# CY8C3866AXI_040 register map
File version: 0.1
CY8C38
Registers are 8-bit, read-write, no defined reset value unless marked. A register's access mark holds for its fields unless they carry their own. Offsets are from the block's base; lines under a group give offsets from that group; [hi:lo] are bit positions; {n}, {i} and the like mark numbered series; 'fields as' and 'values as' point back to an identical list; <NAME> marks a mode.

## Memory map
0x00004382 RTC_1 size 0xF — RTC
0x00004394 USBUART size 0x1D0A — USBFS
0x000043A3 Blink_Timer size 0xB64
0x000043AA ADC size 0x17E0

## RTC_1 — RTC
Base 0x00004382
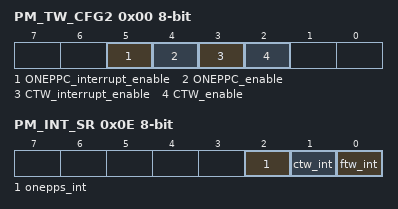
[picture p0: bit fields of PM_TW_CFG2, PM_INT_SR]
0x00 PM_TW_CFG2 — Power timers enable and interrupt enable configuration register
  [5] ONEPPC_interrupt_enable — When set and one pulse-per-second is enabled, an interrupt is issued when the pulse occurs
    1=Enabled (The ONEPPC interrupt is issued. Only if ONEPPC is enabled.); 0=Disabled (No ONEPPC interrupt is issued.)
  [4] ONEPPC_enable
    1=Enabled (The ONEPPC is enabled.); 0=Disabled (The ONEPPC is disabled.)
  [3] CTW_interrupt_enable — An interrupt issue when the CTW reaches the selected interval
    1=Enabled (The CTW interrupt is issued. Only if CTW is enabled.); 0=Disabled (No CTW interrupt is issued.)
  [2] CTW_enable
    1=Enabled (The CTW is enabled.); 0=Disabled (The CTW is disabled.)
0x0E PM_INT_SR — Power Manager Interrupt Status Register
  [2] onepps_int — When set, a onepps event has occured.
  [1] ctw_int — When set, a limited active ready event has occured
  [0] ftw_int — When set, a fast timewheel event has occured

## USBUART — USBFS
Base 0x00004394
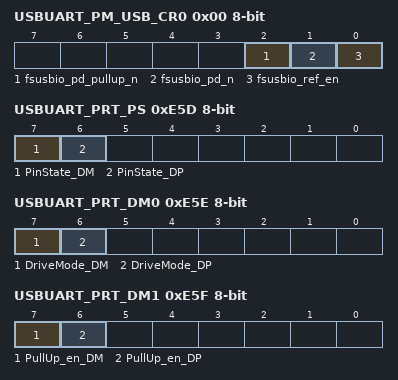
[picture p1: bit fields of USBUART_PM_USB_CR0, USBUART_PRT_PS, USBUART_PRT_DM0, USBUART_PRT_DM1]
0x00 USBUART_PM_USB_CR0 — USB Power Mode Control Register 0
  [2] fsusbio_pd_pullup_n, [1] fsusbio_pd_n, [0] fsusbio_ref_en
0x11 USBUART_PM_ACT_CFG — Active Power Mode Configuration Register
0x21 USBUART_PM_STBY_CFG — Standby Power Mode Configuration Register
0xE5D USBUART_PRT_PS — Port Pin State Register
  [7] PinState_DM ro, [6] PinState_DP ro
0xE5E USBUART_PRT_DM0 — Port Drive Mode Register
  [7] DriveMode_DM, [6] DriveMode_DP
0xE5F USBUART_PRT_DM1 — Port Drive Mode Register
  [7] PullUp_en_DM, [6] PullUp_en_DP
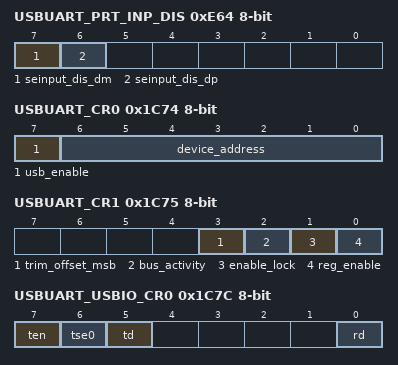
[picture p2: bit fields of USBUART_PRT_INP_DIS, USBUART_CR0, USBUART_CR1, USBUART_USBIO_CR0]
0xE64 USBUART_PRT_INP_DIS — Input buffer disable override
  [7] seinput_dis_dm, [6] seinput_dis_dp
0x1C6C USBUART_EP0_DR0 — bmRequestType
0x1C6D USBUART_EP0_DR1 — bRequest
0x1C6E USBUART_EP0_DR2 — wValueLo
0x1C6F USBUART_EP0_DR3 — wValueHi
0x1C70 USBUART_EP0_DR4 — wIndexLo
0x1C71 USBUART_EP0_DR5 — wIndexHi
0x1C72 USBUART_EP0_DR6 — lengthLo
0x1C73 USBUART_EP0_DR7 — lengthHi
0x1C74 USBUART_CR0 — USB Control Register 0
  [7] usb_enable, [6:0] device_address ro
0x1C75 USBUART_CR1 — USB Control Register 1
  [3] trim_offset_msb, [2] bus_activity, [1] enable_lock, [0] reg_enable
{0x1C6A+0x10*i} USBUART_SIE_EP{i}_CR0 (i=1..8) — The Endpoint{i} Control Register
0x1C7C USBUART_USBIO_CR0 — USBIO Control Register 0
  [7] ten, [6] tse0, [5] td, [0] rd ro
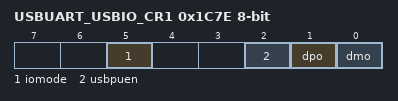
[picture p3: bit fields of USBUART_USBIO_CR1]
0x1C7E USBUART_USBIO_CR1 — USBIO Control Register 1
  [5] iomode, [2] usbpuen, [1] dpo ro, [0] dmo ro
0x1CF8 USBUART_BUF_SIZE — Dedicated Endpoint Buffer Size Register
0x1CFA USBUART_EP_ACTIVE — Endpoint Active Indication Register
0x1CFB USBUART_EP_TYPE — Endpoint Type (IN/OUT) Indication
0x1D09 USBUART_USB_CLK_EN — USB Block Clock Enable Register

## Blink_Timer
Base 0x000043A3
0x00 Blink_Timer_GLOBAL_ENABLE — PM.ACT.CFG
  [3:0] en_timer — Enable timer/counters.
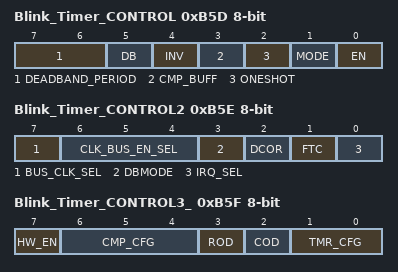
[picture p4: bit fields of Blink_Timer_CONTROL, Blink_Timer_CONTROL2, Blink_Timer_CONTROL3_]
0xB5D Blink_Timer_CONTROL — TMRx.CFG0
  [7:6] DEADBAND_PERIOD
  [5] DB — Deadband mode--Deadband phases phi1 and phi2 are outputted on CMP and TC output pins respectively.
    0=Timer (CMP and TC are output.); 1=Deadband (PHI1 (instead of CMP) and PHI2 (instead of TC) are output.)
  [4] INV — Invert sense of TIMEREN signal
  [3] CMP_BUFF — Buffer compare register. Compare register updates only on timer terminal count.
  [2] ONESHOT — Timer stops upon reaching stop condition defined by TMR_CFG bits. Can be restarted by asserting TIMER RESET or disabling and re-enabling block.
  [1] MODE — Mode. (0 = Timer; 1 = Comparator)
    0=Timer mode. CNT/CMP register holds timer count value.; 1=Comparator mode. CNT/CMP register holds comparator threshold value.
  [0] EN — Enables timer/comparator.
0xB5E Blink_Timer_CONTROL2 — TMRx.CFG1
  [7] BUS_CLK_SEL — Bus Clock selection.
  [6:4] CLK_BUS_EN_SEL — Digital Global Clock selection.
  [3] DBMODE — Deadband mode (asynchronous/synchronous). CMP output pin is also affected when not in deadband mode (CFG0.DEADBAND).
  [2] DCOR — Disable Clear on Read (DCOR) of Status Register SR0.
  [1] FTC — First Terminal Count (FTC). Setting this bit forces a single pulse on the TC pin when first enabled.
    0=Disable_FTC (Disable the single cycle pulse, which signifies the timer is starting.); 1=Enable_FTC (Enable the single cycle pulse, which signifies the timer is starting.)
  [0] IRQ_SEL — Irq selection. (0 = raw interrupts; 1 = status register interrupts)
0xB5F Blink_Timer_CONTROL3_ — TMRx.CFG2
  [7] HW_EN — When set Timer Enable controls counting.
  [6:4] CMP_CFG — Comparator configurations
    0=Equal (Compare Equal); 1=Less_than (Compare Less Than); 2=Less_than_or_equal (Compare Less Than or Equal .); 3=Greater (Compare Greater Than .); 4=Greater_than_or_equal (Compare Greater Than or Equal)
  [3] ROD — Reset On Disable (ROD). Resets internal state of output logic
  [2] COD — Clear On Disable (COD). Clears or gates outputs to zero.
  [1:0] TMR_CFG — Timer configuration (MODE = 0): 000 = Continuous; 001 = Pulsewidth; 010 = Period; 011 = Stop on IRQ
    0=Continuous (Timer runs while EN bit of CFG0 register is set to '1'.); 1=Pulsewidth (Timer runs from positive to negative edge of TIMEREN.); 2=Period (Timer runs from positive to positive edge of TIMEREN.); 3=Irq (Timer runs until IRQ.)
0xB61 Blink_Timer_PERIOD 16-bit — TMRx.PER0 - Assigned Period
0xB63 Blink_Timer_COUNTER 16-bit — TMRx.CNT_CMP0 - Current Down Counter Value
